VERSION ""

NS_ :

BS_: 500

BU_: Vector__XXX

BO_ 273 MSG_111: 8 Vector__XXX
 SG_ Transmission_Oil_Temperature : 32|8@1+ (1,-40) [-40|214] "��" Vector__XXX

BO_ 274 MSG_112: 8 Vector__XXX
 SG_ Gear : 8|4@1+ (1,0) [0|15] "" Vector__XXX

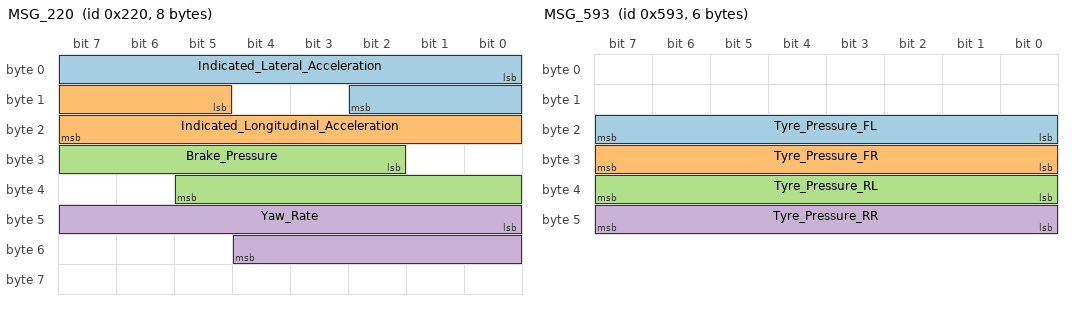
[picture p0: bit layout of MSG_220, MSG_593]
BO_ 544 MSG_220: 8 Vector__XXX
 SG_ Indicated_Lateral_Acceleration : 0|11@1+ (0.01,-10.23) [-10.23|10.24] "m/s��" Vector__XXX
 SG_ Indicated_Longitudinal_Acceleration : 13|11@1+ (0.01,-10.23) [-10.23|10.24] "m/s��" Vector__XXX
 SG_ Brake_Pressure : 26|12@1+ (0.1,0) [0|409.5] "bar" Vector__XXX
 SG_ Yaw_Rate : 40|13@1+ (0.01,-40.95) [-40.95|40.96] "��/s" Vector__XXX

BO_ 790 MSG_316: 8 Vector__XXX
 SG_ Engine_Speed : 16|16@1+ (0.25,0) [0|16383.75] "rpm" Vector__XXX

BO_ 809 MSG_329: 8 Vector__XXX
 SG_ Throttle_Position : 40|8@1+ (0.469484,-15.0235) [-15.0234742|104.6948357] "%" Vector__XXX

BO_ 902 MSG_386: 8 Vector__XXX
 SG_ Wheel_Speed_FL_kph : 0|14@1+ (0.03125,0) [0|511.96875] "km/h" Vector__XXX
 SG_ Wheel_Speed_FL_mph : 0|14@1+ (0.01940625,0) [0|317.93259375] "mph" Vector__XXX
 SG_ Wheel_Speed_FR_kph : 16|14@1+ (0.03125,0) [0|511.96875] "km/h" Vector__XXX
 SG_ Wheel_Speed_FR_mph : 16|14@1+ (0.01940625,0) [0|317.93259375] "mph" Vector__XXX
 SG_ Wheel_Speed_RL_kph : 32|14@1+ (0.03125,0) [0|511.96875] "km/h" Vector__XXX
 SG_ Wheel_Speed_RL_mph : 32|14@1+ (0.01940625,0) [0|317.93259375] "mph" Vector__XXX
 SG_ Wheel_Speed_RR_kph : 48|14@1+ (0.03125,0) [0|511.96875] "km/h" Vector__XXX
 SG_ Wheel_Speed_RR_mph : 48|14@1+ (0.01940625,0) [0|317.93259375] "mph" Vector__XXX

BO_ 916 MSG_394: 8 Vector__XXX
 SG_ Brake_Light : 11|1@1+ (1,0) [0|1] "on/off" Vector__XXX

BO_ 1349 MSG_545: 8 Vector__XXX
 SG_ Battery_Voltage : 24|8@1+ (0.101562,0) [0|25.8984375] "V" Vector__XXX

BO_ 1351 MSG_547: 8 Vector__XXX
 SG_ Intake_Air_Temperature : 16|8@1+ (0.75,-48) [-48|143.25] "��" Vector__XXX

BO_ 1366 MSG_556: 8 Vector__XXX
 SG_ Coolant_Temperature : 8|8@1+ (1,-40) [-40|215] "��" Vector__XXX
 SG_ Engine_Speed : 16|16@1+ (0.25,0) [0|16383.75] "rpm" Vector__XXX
 SG_ Indicated_Vehicle_Speed_kph : 32|8@1+ (1,0) [0|255] "km/h" Vector__XXX
 SG_ Indicated_Vehicle_Speed_mph : 32|8@1+ (0.621,0) [0|158.355] "mph" Vector__XXX

BO_ 1427 MSG_593: 6 Vector__XXX
 SG_ Tyre_Pressure_FL : 16|8@1+ (1,0) [0|255] "" Vector__XXX
 SG_ Tyre_Pressure_FR : 24|8@1+ (1,0) [0|255] "" Vector__XXX
 SG_ Tyre_Pressure_RL : 32|8@1+ (1,0) [0|255] "" Vector__XXX
 SG_ Tyre_Pressure_RR : 40|8@1+ (1,0) [0|255] "" Vector__XXX
